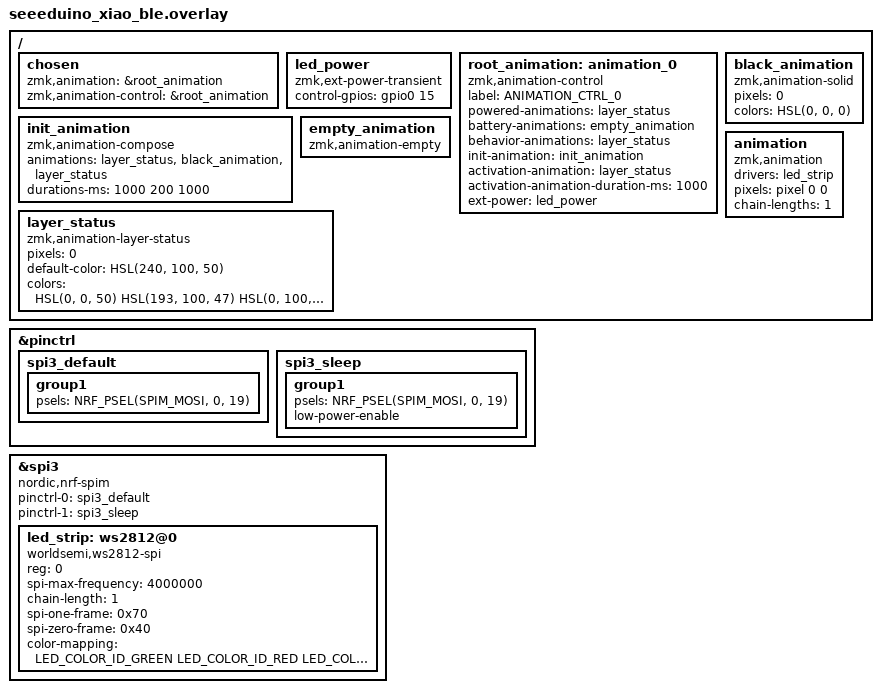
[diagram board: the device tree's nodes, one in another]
// Board-specific overlay for Seeeduino Xiao BLE with soa39 shield
#include <dt-bindings/led/led.h>
#include <dt-bindings/zmk_driver_animation/animation_control.h>
#include <dt-bindings/zmk_driver_animation/animation_trigger.h>

// Enable NFCT pins as GPIO
&pinctrl {
    spi3_default: spi3_default {
        group1 {
            psels = <NRF_PSEL(SPIM_MOSI, 0, 19)>;
        };
    };

    spi3_sleep: spi3_sleep {
        group1 {
            psels = <NRF_PSEL(SPIM_MOSI, 0, 19)>;
            low-power-enable;
        };
    };
};

&spi3 {
    compatible = "nordic,nrf-spim";
    status = "okay";
    pinctrl-0 = <&spi3_default>;
    pinctrl-1 = <&spi3_sleep>;
    pinctrl-names = "default", "sleep";

    led_strip: ws2812@0 {
        compatible = "worldsemi,ws2812-spi";
        status = "okay";
        
        /* SPI */
        reg = <0>;
        spi-max-frequency = <4000000>;

        /* WS2812 */
        chain-length = <1>; /* 1 LED */
        spi-one-frame = <0x70>;
        spi-zero-frame = <0x40>;
        color-mapping = <LED_COLOR_ID_GREEN LED_COLOR_ID_RED LED_COLOR_ID_BLUE>;
    };
};

/ {
    chosen {
        zmk,animation = &root_animation;
        zmk,animation-control = &root_animation;
    };

    led_power: led_power {
        compatible = "zmk,ext-power-transient";
        control-gpios = <&gpio0 15 GPIO_ACTIVE_HIGH>;
    };

    root_animation: animation_0 {
        compatible = "zmk,animation-control";
        label = "ANIMATION_CTRL_0";
        powered-animations = <&layer_status>;
        battery-animations = <&empty_animation>;
        behavior-animations = <&layer_status>;
        init-animation = <&init_animation>;
        activation-animation = <&layer_status>;
        activation-animation-duration-ms = <1000>;
        ext-power = <&led_power>;
    };

    init_animation: init_animation {
        compatible = "zmk,animation-compose";
        animations = <&layer_status &black_animation &layer_status>;
        durations-ms = <1000 200 1000>;
    };

    black_animation: black_animation {
        compatible = "zmk,animation-solid";
        pixels = <0>;
        colors = <HSL(0, 0, 0)>;
    };

    empty_animation: empty_animation {
        compatible = "zmk,animation-empty";
        status = "okay";
    };

    layer_status: layer_status {
        compatible = "zmk,animation-layer-status";
        status = "okay";
        pixels = <0>;
        default-color = <HSL(240, 100, 50)>;
        colors = <
            HSL(0, 0, 50)
            HSL(193, 100, 47)
            HSL(0, 100, 40)
            HSL(60, 100, 50)
            HSL(120, 100, 50)
        >;
    };

    animation: animation {
        compatible = "zmk,animation";
        drivers = <&led_strip>;
        pixels = <&pixel 0 0>;
        chain-lengths = <1>;
    };
};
